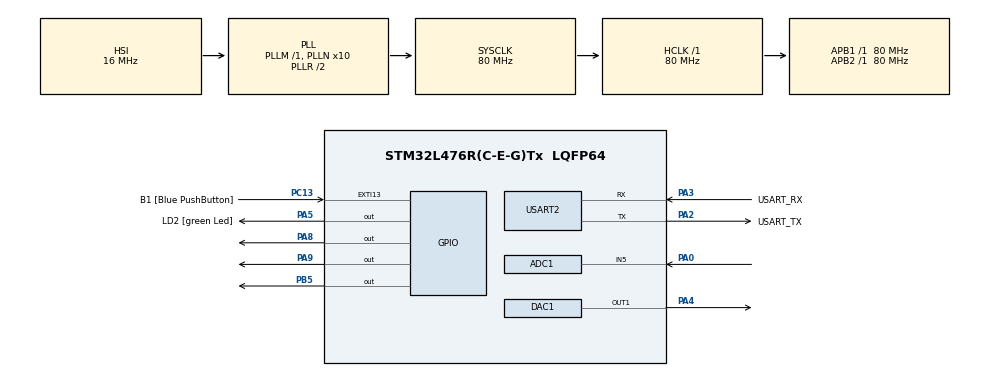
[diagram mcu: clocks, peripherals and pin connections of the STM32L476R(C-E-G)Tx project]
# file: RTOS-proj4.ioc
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ADC1.Channel-0\#ChannelRegularConversion=ADC_CHANNEL_5
ADC1.NbrOfConversionFlag=1
ADC1.OffsetNumber-0\#ChannelRegularConversion=ADC_OFFSET_NONE
ADC1.Rank-0\#ChannelRegularConversion=1
ADC1.SamplingTime-0\#ChannelRegularConversion=ADC_SAMPLETIME_2CYCLES_5
ADC1.master=1
DAC1.DAC_Trigger-DAC_OUT1=DAC_TRIGGER_T6_TRGO
Dma.ADC1.0.Direction=DMA_PERIPH_TO_MEMORY
Dma.ADC1.0.Instance=DMA1_Channel1
Dma.ADC1.0.MemDataAlignment=DMA_MDATAALIGN_HALFWORD
Dma.ADC1.0.MemInc=DMA_MINC_ENABLE
Dma.ADC1.0.Mode=DMA_CIRCULAR
Dma.ADC1.0.PeriphDataAlignment=DMA_PDATAALIGN_HALFWORD
Dma.ADC1.0.PeriphInc=DMA_PINC_DISABLE
Dma.ADC1.0.Priority=DMA_PRIORITY_LOW
Dma.DAC_CH1.1.Direction=DMA_MEMORY_TO_PERIPH
Dma.DAC_CH1.1.Instance=DMA1_Channel3
Dma.DAC_CH1.1.MemDataAlignment=DMA_MDATAALIGN_HALFWORD
Dma.DAC_CH1.1.MemInc=DMA_MINC_ENABLE
Dma.DAC_CH1.1.Mode=DMA_CIRCULAR
Dma.DAC_CH1.1.PeriphDataAlignment=DMA_PDATAALIGN_HALFWORD
Dma.DAC_CH1.1.PeriphInc=DMA_PINC_DISABLE
Dma.DAC_CH1.1.Priority=DMA_PRIORITY_LOW
Dma.Request0=ADC1
Dma.Request1=DAC_CH1
FREERTOS.Tasks01=defaultTask,24,128,StartDefaultTask,Default,NULL,Dynamic,NULL,NULL
FREERTOS.configTOTAL_HEAP_SIZE=24000
Mcu.Family=STM32L4
Mcu.Name=STM32L476R(C-E-G)Tx
Mcu.Package=LQFP64
NVIC.ADC1_2_IRQn=true\:5\:0\:false\:false\:true\:true\:true\:true\:true
NVIC.DMA1_Channel1_IRQn=true\:5\:0\:false\:false\:true\:true\:false\:true\:true
NVIC.DMA1_Channel3_IRQn=true\:5\:0\:false\:false\:true\:true\:false\:true\:true
NVIC.PriorityGroup=NVIC_PRIORITYGROUP_4
NVIC.TIM1_BRK_TIM15_IRQn=true\:5\:0\:false\:false\:true\:true\:true\:true\:true
NVIC.USART2_IRQn=true\:5\:0\:false\:false\:true\:true\:true\:true\:true
PA0.Signal=ADCx_IN5
PA13\ (JTMS-SWDIO).GPIO_Label=TMS
PA13\ (JTMS-SWDIO).Mode=Serial_Wire
PA13\ (JTMS-SWDIO).Signal=SYS_JTMS-SWDIO
PA14\ (JTCK-SWCLK).GPIO_Label=TCK
PA14\ (JTCK-SWCLK).Mode=Serial_Wire
PA14\ (JTCK-SWCLK).Signal=SYS_JTCK-SWCLK
PA2.GPIO_Label=USART_TX
PA2.GPIO_Mode=GPIO_MODE_AF_PP
PA2.GPIO_PuPd=GPIO_NOPULL
PA2.GPIO_Speed=GPIO_SPEED_FREQ_VERY_HIGH
PA2.Mode=Asynchronous
PA2.Signal=USART2_TX
PA3.GPIO_Label=USART_RX
PA3.GPIO_Mode=GPIO_MODE_AF_PP
PA3.GPIO_PuPd=GPIO_NOPULL
PA3.GPIO_Speed=GPIO_SPEED_FREQ_VERY_HIGH
PA3.Mode=Asynchronous
PA3.Signal=USART2_RX
PA4.Signal=SharedAnalog_PA4
PA5.GPIO_Label=LD2 [green Led]
PA5.GPIO_ModeDefaultOutputPP=GPIO_MODE_OUTPUT_PP
PA5.GPIO_PuPd=GPIO_NOPULL
PA5.GPIO_Speed=GPIO_SPEED_FREQ_LOW
PA5.Signal=GPIO_Output
PA8.Signal=GPIO_Output
PA9.Signal=GPIO_Output
PB3\ (JTDO-TRACESWO).GPIO_Label=SWO
PB3\ (JTDO-TRACESWO).Signal=SYS_JTDO-SWO
PB5.Signal=GPIO_Output
PC13.GPIO_Label=B1 [Blue PushButton]
PC13.GPIO_ModeDefaultEXTI=GPIO_MODE_IT_FALLING
PC13.GPIO_PuPd=GPIO_NOPULL
PC13.Signal=GPXTI13
PC14-OSC32_IN\ (PC14).Mode=LSE-External-Oscillator
PC14-OSC32_IN\ (PC14).Signal=RCC_OSC32_IN
PC15-OSC32_OUT\ (PC15).Mode=LSE-External-Oscillator
PC15-OSC32_OUT\ (PC15).Signal=RCC_OSC32_OUT
PH0-OSC_IN\ (PH0).Signal=RCC_OSC_IN
PH1-OSC_OUT\ (PH1).Signal=RCC_OSC_OUT
ProjectManager.HeapSize=0x200
ProjectManager.StackSize=0x400
ProjectManager.TargetToolchain=STM32CubeIDE
RCC.ADCFreq_Value=64000000
RCC.AHBFreq_Value=80000000
RCC.APB1Freq_Value=80000000
RCC.APB1TimFreq_Value=80000000
RCC.APB2Freq_Value=80000000
RCC.APB2TimFreq_Value=80000000
RCC.CortexFreq_Value=80000000
RCC.HCLKFreq_Value=80000000
RCC.HSE_VALUE=8000000
RCC.HSI_VALUE=16000000
RCC.MSI_VALUE=4000000
RCC.PLLN=10
RCC.PLLSourceVirtual=RCC_PLLSOURCE_HSI
RCC.PREFETCH_ENABLE=1
RCC.SYSCLKFreq_VALUE=80000000
RCC.SYSCLKSource=RCC_SYSCLKSOURCE_PLLCLK
RCC.USBFreq_Value=64000000
RCC.VCOOutputFreq_Value=160000000
SH.ADCx_IN5.0=ADC1_IN5,IN5-Single-Ended
SH.SharedAnalog_PA4.0=GPIO_Analog
SH.SharedAnalog_PA4.1=DAC1_OUT1,DAC_OUT1
TIM15.AutoReloadPreload=TIM_AUTORELOAD_PRELOAD_ENABLE
TIM15.Period=249
TIM15.Prescaler=79
TIM2.AutoReloadPreload=TIM_AUTORELOAD_PRELOAD_ENABLE
TIM2.Period=4000
TIM6.AutoReloadPreload=TIM_AUTORELOAD_PRELOAD_ENABLE
TIM6.Period=49
TIM6.Prescaler=79
TIM6.TIM_MasterOutputTrigger=TIM_TRGO_UPDATE
USART2.VirtualMode-Asynchronous=VM_ASYNC
VP_FREERTOS_VS_CMSIS_V2.Mode=CMSIS_V2
VP_TIM15_VS_ClockSourceINT.Mode=Internal
VP_TIM2_VS_ClockSourceINT.Mode=Internal
VP_TIM2_VS_ClockSourceITR.Mode=TriggerSource_ITR0
VP_TIM2_VS_ControllerModeTrigger.Mode=Trigger Mode
VP_TIM6_VS_ClockSourceINT.Mode=Enable_Timer
board=NUCLEO-L476RG

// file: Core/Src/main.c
/* USER CODE BEGIN Header */
/**
  ******************************************************************************
  * @file           : main.c
  * @brief          : Main program body
  ******************************************************************************
  * @attention
  *
  * Copyright (c) 2025 STMicroelectronics.
  * All rights reserved.
  *
  * This software is licensed under terms that can be found in the LICENSE file
  * in the root directory of this software component.
  * If no LICENSE file comes with this software, it is provided AS-IS.
  *
  ******************************************************************************
  */
/* USER CODE END Header */
#include "main.h"
#include "cmsis_os.h"
#include "adc.h"
#include "dac.h"
#include "dma.h"
#include "tim.h"
#include "usart.h"
#include "gpio.h"
#include "7seg.h"

void SystemClock_Config(void);
void MX_FREERTOS_Init(void);

int main(void)
{

  /* MCU Configuration--------------------------------------------------------*/

  /* Reset of all peripherals, Initializes the Flash interface and the Systick. */
  HAL_Init();

  /* Configure the system clock */
  SystemClock_Config();

  /* Initialize all configured peripherals */
  MX_GPIO_Init();
  MX_DMA_Init();
  MX_USART2_UART_Init();
  MX_ADC1_Init();
  MX_DAC1_Init();
  MX_TIM2_Init();
  MX_TIM6_Init();
  MX_TIM15_Init();
  /* USER CODE BEGIN 2 */

  initSeg();
  multiplexSegment(1234);
  HAL_TIM_Base_Start_IT(&htim15);

  /* USER CODE END 2 */

  /* Init scheduler */
  osKernelInitialize();  /* Call init function for freertos objects (in cmsis_os2.c) */
  MX_FREERTOS_Init();

  /* Start scheduler */
  osKernelStart();

  /* We should never get here as control is now taken by the scheduler */

  /* Infinite loop */
  while (1)
  {

  }
}

void SystemClock_Config(void)
{
  RCC_OscInitTypeDef RCC_OscInitStruct = {0};
  RCC_ClkInitTypeDef RCC_ClkInitStruct = {0};

  /** Configure the main internal regulator output voltage
  */
  if (HAL_PWREx_ControlVoltageScaling(PWR_REGULATOR_VOLTAGE_SCALE1) != HAL_OK)
  {
    Error_Handler();
  }

  /** Initializes the RCC Oscillators according to the specified parameters
  * in the RCC_OscInitTypeDef structure.
  */
  RCC_OscInitStruct.OscillatorType = RCC_OSCILLATORTYPE_HSI;
  RCC_OscInitStruct.HSIState = RCC_HSI_ON;
  RCC_OscInitStruct.HSICalibrationValue = RCC_HSICALIBRATION_DEFAULT;
  RCC_OscInitStruct.PLL.PLLState = RCC_PLL_ON;
  RCC_OscInitStruct.PLL.PLLSource = RCC_PLLSOURCE_HSI;
  RCC_OscInitStruct.PLL.PLLM = 1;
  RCC_OscInitStruct.PLL.PLLN = 10;
  RCC_OscInitStruct.PLL.PLLP = RCC_PLLP_DIV7;
  RCC_OscInitStruct.PLL.PLLQ = RCC_PLLQ_DIV2;
  RCC_OscInitStruct.PLL.PLLR = RCC_PLLR_DIV2;
  if (HAL_RCC_OscConfig(&RCC_OscInitStruct) != HAL_OK)
  {
    Error_Handler();
  }

  /** Initializes the CPU, AHB and APB buses clocks
  */
  RCC_ClkInitStruct.ClockType = RCC_CLOCKTYPE_HCLK|RCC_CLOCKTYPE_SYSCLK
                              |RCC_CLOCKTYPE_PCLK1|RCC_CLOCKTYPE_PCLK2;
  RCC_ClkInitStruct.SYSCLKSource = RCC_SYSCLKSOURCE_PLLCLK;
  RCC_ClkInitStruct.AHBCLKDivider = RCC_SYSCLK_DIV1;
  RCC_ClkInitStruct.APB1CLKDivider = RCC_HCLK_DIV1;
  RCC_ClkInitStruct.APB2CLKDivider = RCC_HCLK_DIV1;

  if (HAL_RCC_ClockConfig(&RCC_ClkInitStruct, FLASH_LATENCY_4) != HAL_OK)
  {
    Error_Handler();
  }
}

void Error_Handler(void)
{
  __disable_irq();
  while (1)
  {
  }
}
